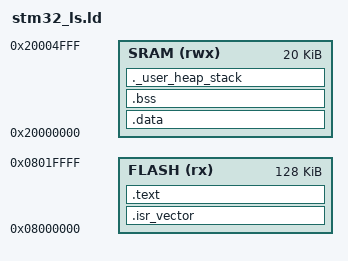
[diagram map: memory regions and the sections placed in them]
ENTRY(Reset_Handler)

MEMORY
{
    FLASH (rx)  : ORIGIN = 0x08000000, LENGTH = 128K
    SRAM  (rwx) : ORIGIN = 0x20000000, LENGTH = 20K
}

_estack = ORIGIN(SRAM) + LENGTH(SRAM);

SECTIONS
{
    .isr_vector :
    {
        KEEP(*(.isr_vector))
    } > FLASH

    .text :
    {
        *(.text)
        *(.text*)
        *(.rodata)
        *(.rodata*)
        *(.init)
        *(.fini)
        *(.eh_frame)
        . = ALIGN(4);
        _etext = .;
    } > FLASH

    .data : AT (ADDR(.text) + SIZEOF(.text))
    {
        _sdata = .;
        *(.data)
        *(.data*)
        . = ALIGN(4);
        _edata = .;
    } > SRAM

    .bss :
    {
        _sbss = .;
        *(.bss)
        *(.bss*)
        *(COMMON)
        . = ALIGN(4);
        _ebss = .;
    } > SRAM

    ._user_heap_stack :
    {
        . = ALIGN(8);
        PROVIDE ( end = . );
        PROVIDE ( _end = . );
        . = . + 0x400; 
        PROVIDE ( _heap_end = . );
    } > SRAM
}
